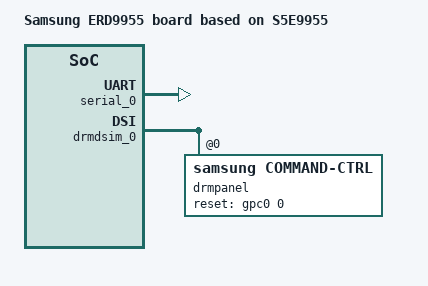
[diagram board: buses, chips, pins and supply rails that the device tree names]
/*
 * SAMSUNG S5E9955 board device tree source
 *
 * Copyright (c) 2023 Samsung Electronics Co., Ltd.
 *		http://www.samsung.com
 *
 * This program is free software; you can redistribute it and/or modify
 * it under the terms of the GNU General Public License version 2 as
 * published by the Free Software Foundation.
 */

/dts-v1/;
/plugin/;

#include <dt-bindings/gpio/gpio.h>
//#include <dt-bindings/clock/s5e9955.h>
#include <dt-bindings/interrupt-controller/s5e9955.h>
#include "panel/samsung-emulation-video-panel.dtsi"

#define BOARD_ID	0x0
#define BOARD_REV	0x0

/ {
	compatible = "samsung,s5e9955", "samsung,ERD9955";
	board_id = <BOARD_ID>;
	board_rev = <BOARD_REV>;

	fragment@model {
		target-path = "/";
		__overlay__ {
			#address-cells = <2>;
			#size-cells = <1>;

			model = "Samsung ERD9955 board based on S5E9955";
		}; /* end of __overlay__ */
	}; /* end of fragment */
}; /* end of root */

&chosen {
        bootargs_ext = "panic_on_warn=1";
};

&serial_0 {
	status = "okay";
};

&drmdsim_0 {
	#address-cells = <1>;
	#size-cells = <0>;
	drmpanel {
		compatible = "samsung,command-ctrl";
		/* reset, power */
		reset-gpios = <&gpc0 0 GPIO_ACTIVE_HIGH>;
		reg = <0>;
		pinctrl-names = "default";
		pinctrl-0 = <&ddi_rst>;

		default-panel = "samsung_emulation_video_panel";
	};
};

&drmdecon_0 {
	op_mode = <0>;
};
